# DemoMCU register map
Vendor: DemoCorp; Series: DemoSeries; File version: 1.0
Minimal demo device used by the regforge test suite
CPU: CM0PLUS r0p1, little endian, MPU, no FPU, VTOR, 2 interrupt priority bits, 32 interrupts
Registers are read-write, no defined reset value unless marked. A register's access mark holds for its fields unless they carry their own. Offsets are from the block's base; lines under a group give offsets from that group; [hi:lo] are bit positions; {n}, {i} and the like mark numbered series; 'fields as' and 'values as' point back to an identical list; <NAME> marks a mode.

## Memory map
0x40000000 TIM2 size 0x20 — General-purpose timer
0x40000400 TIM3 size 0x20 — General-purpose timer
0x40004000 UART0 blocks up to offset 0x28 — Universal async receiver/transmitter
0x40004400 UART1 blocks up to offset 0x28 — UART, instance 1
0x40008000 SPI0 size 0x400 — Serial peripheral interface
0x40008400 SPI1 size 0x400 — Serial peripheral interface
0x40010000 TIM1 size 0x20 — Advanced timer
0x40012000 ADC0 size 0x10 — Analog-to-digital converter
0x40012400 ADC1 size 0x10 — ADC, instance 1
0x40013000 WDT0 size 0x10 — Watchdog timer
0x40013400 WDT1 size 0x8 — Watchdog, instance 1 (adds a reload register)
0x40014000 CRC size 0x8 — Cyclic redundancy check
0x40015000 PWM{x} (x=A,B; step 0x100) size 0x100 — Pulse-width modulator
0x40016000 DMA size 0x100 — Direct memory access
0x40020000 GPIOA size 0x20 — General purpose I/O port A

## Interrupts
20 UART0 — UART0 global interrupt
21 UART1 — UART1 global interrupt
25 TIM1_UP (TIM1) — TIM1 update
26 TIM1_BRK (TIM1) — TIM1 break
27 ADC0 — ADC0 conversion complete
28 ADC1 — ADC1 conversion complete
30 SPI0 — SPI0 interrupt
30 SPI1 — SPI1 interrupt

## Further device data
tuning=calibrated

## GPIOA — General purpose I/O port A
Base 0x40020000
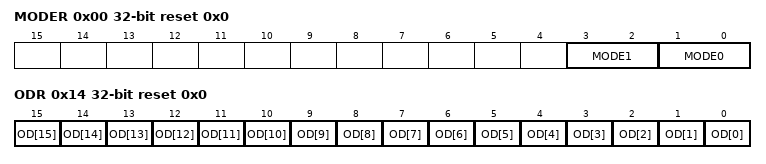
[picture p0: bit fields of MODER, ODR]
0x00 MODER 32-bit reset 0x0 — Mode register
  [2n+1:2n] MODE{n} (n=0..1) — Pin mode
    0=INPUT; 1=OUTPUT; 2=ALTERNATE; 3=ANALOG
0x10 IDR ro — Input data register
0x14 ODR 32-bit reset 0x0 (reset mask 0xFFFF) — Output data register
  [n] OD[{n}] (n=0..15) — Port output data bit

## UART0 — Universal async receiver/transmitter
Base 0x40004000
Same registers: UART1 0x40004400
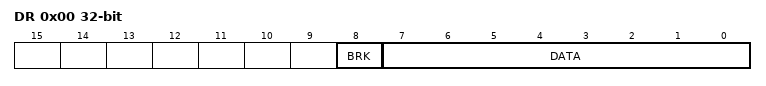
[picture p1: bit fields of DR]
0x00 DR — Data register
  [8] BRK — Send a break condition
    on write: 1=SEND
  [7:0] DATA — Received byte on read, byte to send on write
    on read: 0=RX_IDLE | on write: 0=TX_NULL
0x04 SR ro — Status register
  [0] TXE — Transmit buffer empty
    on read: 0=FULL; 1=EMPTY

## SPI0 — Serial peripheral interface
Base 0x40008000
Same registers: SPI1 0x40008400
0x00 CR — Control register
0x04 DR — Data register
0x04 RXD ro (alternate view of DR) — Receive data (read view of DR)

## TIM1 — Advanced timer
Base 0x40010000
0x00 CR1 — Control register 1
0x04 ARR — Auto-reload register
0x08 RCR — Repetition counter (advanced only)
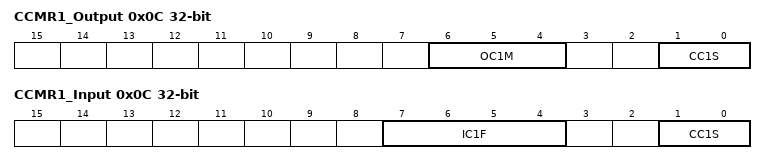
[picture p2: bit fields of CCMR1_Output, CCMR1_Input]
0x0C CCMR1_Output — Capture/compare mode (output)
  [6:4] OC1M — Output compare 1 mode
  [1:0] CC1S — Capture/compare 1 selection
0x0C CCMR1_Input (alternate view of CCMR1_Output) — Capture/compare mode (input)
  [7:4] IC1F — Input capture 1 filter
  [1:0] CC1S — Capture/compare 1 selection

## TIM2 — General-purpose timer
Base 0x40000000
Same registers: TIM3 0x40000400
0x00 CR1 — Control register 1
0x04 ARR — Auto-reload register

## ADC0 — Analog-to-digital converter
Base 0x40012000
Same registers: ADC1 0x40012400
0x00 CR — Control register
0x04 DR ro — Data register
0x04 DR ro (Cal view) — Calibrated data (alternate group of DR)

## WDT0 — Watchdog timer
Base 0x40013000
0x00 CR — Control register

## WDT1 — Watchdog, instance 1 (adds a reload register)
Base 0x40013400
0x00 CR — Control register
0x04 RELOAD — Reload value

## CRC — Cyclic redundancy check
Base 0x40014000
0x00 DR — Data register
0x00 DR8 8-bit (alternate view of DR) — Byte-wide view of DR
0x00 DR16 16-bit (alternate view of DR) — Half-word view of DR

## PWM{x} — Pulse-width modulator
Base 0x40015000; array of 2, step 0x100
0x00 CTRL — Control register
{0x10+4i} CC[{i}] (i=0..3) reset 0x0 — Capture/compare channel
{0x10+4i} CCI[{i}] (i=0..3) reset 0x0 (alternate view of CC[{i}]) — Capture/compare channel (input capture view)
{0x20+8i} DT{i} (i=0..1) — Dead time
{0x20+8i} DTR{i} (i=0..1) (alternate view of DT{i}) — Dead time (raw view)

## DMA — Direct memory access
Base 0x40016000
0x00 CFG — Global configuration
{0x10+0x10*i} CH[{i}] (i=0..3) group — DMA channel
  0x00 CTRL — Channel control
    [0] EN — Channel enable
  0x04 SRC — Source address
  0x08 DST — Destination address
  0x0C XFER_Mem — Transfer control (memory side)
  0x0C XFER_Periph (alternate view of XFER_Mem) — Transfer control (peripheral side)
0x50 STAT group — Status block
  0x00 FLAGS ro — Channel flags
  0x04 ERR ro — Error flags

## Licence text in the file
Copyright (c) 2024 DemoCorp. Licensed under the Apache License, Version 2.0.
